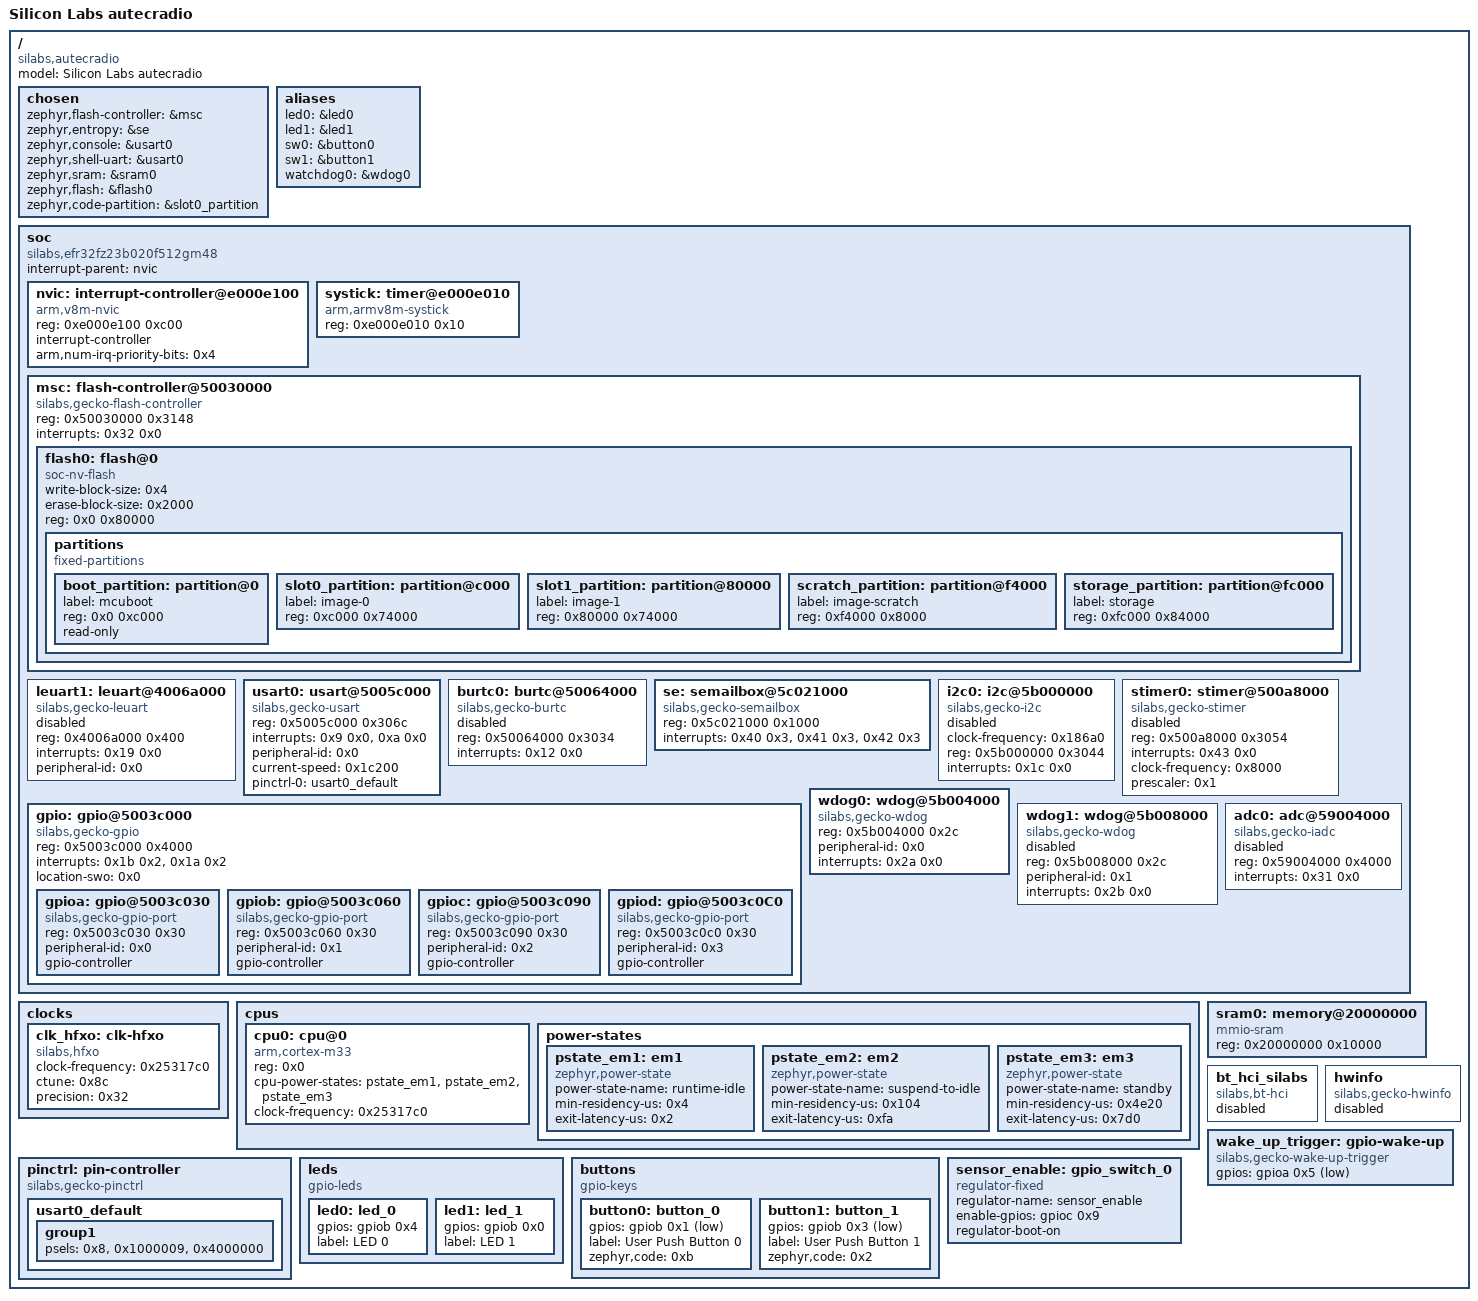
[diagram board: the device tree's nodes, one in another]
/dts-v1/;

/ {
	#address-cells = < 0x1 >;
	#size-cells = < 0x1 >;
	model = "Silicon Labs autecradio";
	compatible = "silabs,autecradio", "silabs,efr32zg23";
	chosen {
		zephyr,flash-controller = &msc;
		zephyr,entropy = &se;
		zephyr,console = &usart0;
		zephyr,shell-uart = &usart0;
		zephyr,sram = &sram0;
		zephyr,flash = &flash0;
		zephyr,code-partition = &slot0_partition;
	};
	aliases {
		led0 = &led0;
		led1 = &led1;
		sw0 = &button0;
		sw1 = &button1;
		watchdog0 = &wdog0;
	};
	soc {
		#address-cells = < 0x1 >;
		#size-cells = < 0x1 >;
		compatible = "silabs,efr32fz23b020f512gm48", "silabs,efr32zg23", "silabs,efr32", "simple-bus";
		interrupt-parent = < &nvic >;
		ranges;
		nvic: interrupt-controller@e000e100 {
			#address-cells = < 0x1 >;
			compatible = "arm,v8m-nvic";
			reg = < 0xe000e100 0xc00 >;
			interrupt-controller;
			#interrupt-cells = < 0x2 >;
			arm,num-irq-priority-bits = < 0x4 >;
			phandle = < 0x1 >;
		};
		systick: timer@e000e010 {
			compatible = "arm,armv8m-systick";
			reg = < 0xe000e010 0x10 >;
		};
		msc: flash-controller@50030000 {
			compatible = "silabs,gecko-flash-controller";
			reg = < 0x50030000 0x3148 >;
			interrupts = < 0x32 0x0 >;
			#address-cells = < 0x1 >;
			#size-cells = < 0x1 >;
			flash0: flash@0 {
				compatible = "soc-nv-flash";
				write-block-size = < 0x4 >;
				erase-block-size = < 0x2000 >;
				reg = < 0x0 0x80000 >;
				partitions {
					compatible = "fixed-partitions";
					#address-cells = < 0x1 >;
					#size-cells = < 0x1 >;
					boot_partition: partition@0 {
						label = "mcuboot";
						reg = < 0x0 0xc000 >;
						read-only;
					};
					slot0_partition: partition@c000 {
						label = "image-0";
						reg = < 0xc000 0x74000 >;
					};
					slot1_partition: partition@80000 {
						label = "image-1";
						reg = < 0x80000 0x74000 >;
					};
					scratch_partition: partition@f4000 {
						label = "image-scratch";
						reg = < 0xf4000 0x8000 >;
					};
					storage_partition: partition@fc000 {
						label = "storage";
						reg = < 0xfc000 0x84000 >;
					};
				};
			};
		};
		leuart1: leuart@4006a000 {
			compatible = "silabs,gecko-leuart";
			reg = < 0x4006a000 0x400 >;
			interrupts = < 0x19 0x0 >;
			peripheral-id = < 0x0 >;
			status = "disabled";
		};
		usart0: usart@5005c000 {
			compatible = "silabs,gecko-usart";
			reg = < 0x5005c000 0x306c >;
			interrupts = < 0x9 0x0 >, < 0xa 0x0 >;
			interrupt-names = "rx", "tx";
			peripheral-id = < 0x0 >;
			status = "okay";
			current-speed = < 0x1c200 >;
			pinctrl-0 = < &usart0_default >;
			pinctrl-names = "default";
		};
		burtc0: burtc@50064000 {
			compatible = "silabs,gecko-burtc";
			reg = < 0x50064000 0x3034 >;
			interrupts = < 0x12 0x0 >;
			status = "disabled";
		};
		se: semailbox@5c021000 {
			compatible = "silabs,gecko-semailbox";
			reg = < 0x5c021000 0x1000 >;
			status = "okay";
			interrupts = < 0x40 0x3 >, < 0x41 0x3 >, < 0x42 0x3 >;
			interrupt-names = "SETAMPERHOST", "SEMBRX", "SEMBTX";
		};
		i2c0: i2c@5b000000 {
			compatible = "silabs,gecko-i2c";
			clock-frequency = < 0x186a0 >;
			#address-cells = < 0x1 >;
			#size-cells = < 0x0 >;
			reg = < 0x5b000000 0x3044 >;
			interrupts = < 0x1c 0x0 >;
			status = "disabled";
		};
		stimer0: stimer@500a8000 {
			compatible = "silabs,gecko-stimer";
			reg = < 0x500a8000 0x3054 >;
			interrupts = < 0x43 0x0 >;
			clock-frequency = < 0x8000 >;
			prescaler = < 0x1 >;
			status = "disabled";
		};
		gpio: gpio@5003c000 {
			compatible = "silabs,gecko-gpio";
			reg = < 0x5003c000 0x4000 >;
			interrupts = < 0x1b 0x2 >, < 0x1a 0x2 >;
			interrupt-names = "GPIO_EVEN", "GPIO_ODD";
			ranges;
			#address-cells = < 0x1 >;
			#size-cells = < 0x1 >;
			location-swo = < 0x0 >;
			status = "okay";
			gpioa: gpio@5003c030 {
				compatible = "silabs,gecko-gpio-port";
				reg = < 0x5003c030 0x30 >;
				peripheral-id = < 0x0 >;
				gpio-controller;
				#gpio-cells = < 0x2 >;
				status = "okay";
				phandle = < 0x7 >;
			};
			gpiob: gpio@5003c060 {
				compatible = "silabs,gecko-gpio-port";
				reg = < 0x5003c060 0x30 >;
				peripheral-id = < 0x1 >;
				gpio-controller;
				#gpio-cells = < 0x2 >;
				status = "okay";
				phandle = < 0x6 >;
			};
			gpioc: gpio@5003c090 {
				compatible = "silabs,gecko-gpio-port";
				reg = < 0x5003c090 0x30 >;
				peripheral-id = < 0x2 >;
				gpio-controller;
				#gpio-cells = < 0x2 >;
				status = "okay";
				phandle = < 0x8 >;
			};
			gpiod: gpio@5003c0C0 {
				compatible = "silabs,gecko-gpio-port";
				reg = < 0x5003c0c0 0x30 >;
				peripheral-id = < 0x3 >;
				gpio-controller;
				#gpio-cells = < 0x2 >;
				status = "okay";
			};
		};
		wdog0: wdog@5b004000 {
			compatible = "silabs,gecko-wdog";
			reg = < 0x5b004000 0x2c >;
			peripheral-id = < 0x0 >;
			interrupts = < 0x2a 0x0 >;
			status = "okay";
		};
		wdog1: wdog@5b008000 {
			compatible = "silabs,gecko-wdog";
			reg = < 0x5b008000 0x2c >;
			peripheral-id = < 0x1 >;
			interrupts = < 0x2b 0x0 >;
			status = "disabled";
		};
		adc0: adc@59004000 {
			compatible = "silabs,gecko-iadc";
			reg = < 0x59004000 0x4000 >;
			interrupts = < 0x31 0x0 >;
			status = "disabled";
			#io-channel-cells = < 0x1 >;
		};
	};
	clocks {
		clk_hfxo: clk-hfxo {
			#clock-cells = < 0x0 >;
			compatible = "silabs,hfxo";
			clock-frequency = < 0x25317c0 >;
			ctune = < 0x8c >;
			precision = < 0x32 >;
		};
	};
	cpus {
		#address-cells = < 0x1 >;
		#size-cells = < 0x0 >;
		cpu0: cpu@0 {
			device_type = "cpu";
			compatible = "arm,cortex-m33";
			reg = < 0x0 >;
			cpu-power-states = < &pstate_em1 &pstate_em2 &pstate_em3 >;
			clock-frequency = < 0x25317c0 >;
		};
		power-states {
			pstate_em1: em1 {
				compatible = "zephyr,power-state";
				power-state-name = "runtime-idle";
				min-residency-us = < 0x4 >;
				exit-latency-us = < 0x2 >;
				phandle = < 0x3 >;
			};
			pstate_em2: em2 {
				compatible = "zephyr,power-state";
				power-state-name = "suspend-to-idle";
				min-residency-us = < 0x104 >;
				exit-latency-us = < 0xfa >;
				phandle = < 0x4 >;
			};
			pstate_em3: em3 {
				compatible = "zephyr,power-state";
				power-state-name = "standby";
				min-residency-us = < 0x4e20 >;
				exit-latency-us = < 0x7d0 >;
				phandle = < 0x5 >;
			};
		};
	};
	sram0: memory@20000000 {
		device_type = "memory";
		compatible = "mmio-sram";
		reg = < 0x20000000 0x10000 >;
	};
	bt_hci_silabs: bt_hci_silabs {
		compatible = "silabs,bt-hci";
		status = "disabled";
	};
	pinctrl: pin-controller {
		compatible = "silabs,gecko-pinctrl";
		usart0_default: usart0_default {
			phandle = < 0x2 >;
			group1 {
				psels = < 0x8 >, < 0x1000009 >, < 0x4000000 >;
			};
		};
	};
	hwinfo: hwinfo {
		compatible = "silabs,gecko-hwinfo";
		status = "disabled";
	};
	leds {
		compatible = "gpio-leds";
		led0: led_0 {
			gpios = < &gpiob 0x4 0x0 >;
			label = "LED 0";
		};
		led1: led_1 {
			gpios = < &gpiob 0x0 0x0 >;
			label = "LED 1";
		};
	};
	buttons {
		compatible = "gpio-keys";
		button0: button_0 {
			gpios = < &gpiob 0x1 0x1 >;
			label = "User Push Button 0";
			zephyr,code = < 0xb >;
		};
		button1: button_1 {
			gpios = < &gpiob 0x3 0x1 >;
			label = "User Push Button 1";
			zephyr,code = < 0x2 >;
		};
	};
	wake_up_trigger: gpio-wake-up {
		compatible = "silabs,gecko-wake-up-trigger";
		gpios = < &gpioa 0x5 0x1 >;
	};
	sensor_enable: gpio_switch_0 {
		compatible = "regulator-fixed";
		regulator-name = "sensor_enable";
		enable-gpios = < &gpioc 0x9 0x0 >;
		regulator-boot-on;
	};
};
